# AT32F403Axx register map
Vendor: Keil; Series: AT32F403A; File version: 1.0
CPU: CM4 r0p1, little endian, no MPU, FPU, 4 interrupt priority bits
Registers are 32-bit, read-write, reset 0x0 unless marked. A register's access mark holds for its fields unless they carry their own. Offsets are from the block's base; [hi:lo] are bit positions.

## TMR10 — General purpose timer
Base 0x40015000
Same registers: TMR13 0x40001C00, TMR14 0x40002000, TMR11 0x40015400
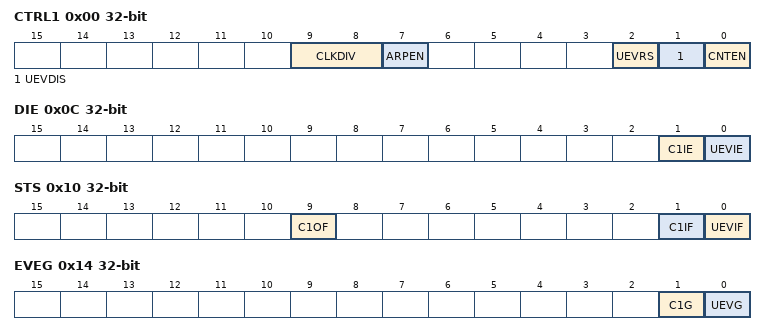
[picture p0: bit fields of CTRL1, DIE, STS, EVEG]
0x00 CTRL1 — control register 1
  [9:8] CLKDIV — Clock division
  [7] ARPEN — Auto-reload preload enable
  [2] UEVRS — Update request source
  [1] UEVDIS — Update disable
  [0] CNTEN — Counter enable
0x0C DIE — DMA/Interrupt enable register
  [1] C1IE — Capture/Compare 1 interrupt enable
  [0] UEVIE — Update interrupt enable
0x10 STS — status register
  [9] C1OF — Capture/Compare 1 overcapture flag
  [1] C1IF — Capture/compare 1 interrupt flag
  [0] UEVIF — Update interrupt flag
0x14 EVEG — event generation register
  [1] C1G — Capture/compare 1 generation
  [0] UEVG — Update generation
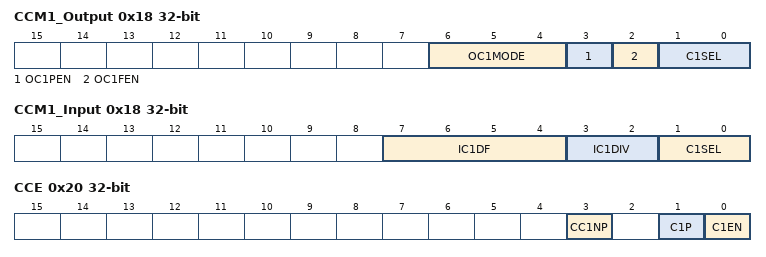
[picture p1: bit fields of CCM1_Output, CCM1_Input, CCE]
0x18 CCM1_Output — capture/compare mode register (output mode)
  [6:4] OC1MODE — Output Compare 1 mode
  [3] OC1PEN — Output Compare 1 preload enable
  [2] OC1FEN — Output Compare 1 fast enable
  [1:0] C1SEL — Capture/Compare 1 selection
0x18 CCM1_Input (alternate view of CCM1_Output) — capture/compare mode register (input mode)
  [7:4] IC1DF — Input capture 1 filter
  [3:2] IC1DIV — Input capture 1 prescaler
  [1:0] C1SEL — Capture/Compare 1 selection
0x20 CCE — capture/compare enable register
  [3] CC1NP — Capture/Compare 1 output Polarity
  [1] C1P — Capture/Compare 1 output Polarity
  [0] C1EN — Capture/Compare 1 output enable
0x24 CNT — counter
  [15:0] CNT — counter value
0x28 DIV — prescaler
  [15:0] DIV — Prescaler value
0x2C AR — auto-reload register
  [15:0] AR — Auto-reload value
0x34 CC1 — capture/compare register 1
  [15:0] CC1 — Capture/Compare 1 value

## ACC — HSI Auto Clock Calibration
Base 0x40015800
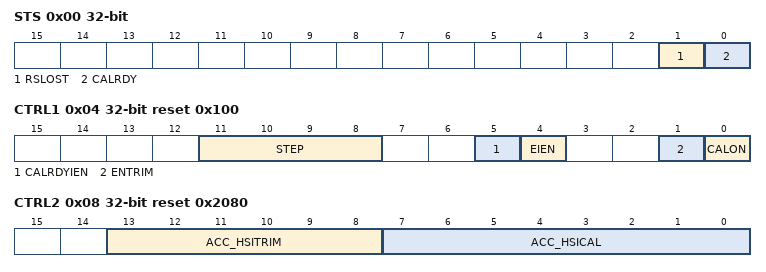
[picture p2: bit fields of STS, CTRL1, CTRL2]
0x00 STS — status register
  [1] RSLOST — Reference Signal Lost
  [0] CALRDY — Internal high-speed clock calibration ready
0x04 CTRL1 reset 0x100 — control register 1
  [11:8] STEP
  [5] CALRDYIEN — CALRDY interrupt enable
  [4] EIEN — RSLOST error interrupt enable
  [1] ENTRIM — Enable trim
  [0] CALON — Calibration on
0x08 CTRL2 reset 0x2080 — control register 2
  [13:8] ACC_HSITRIM ro — Internal high-speed auto clock trimming
  [7:0] ACC_HSICAL ro — Internal high-speed auto clock calibration
0x0C C1 reset 0x1F2C — compare value 1
  [15:0] C1 — Compare 1
0x10 C2 reset 0x1F40 — compare value 2
  [15:0] C2 — Compare 2
0x14 C3 reset 0x1F54 — compare value 3
  [15:0] C3 — Compare 3

## TMR6 — Basic timer
Base 0x40001000
Same registers: TMR7 0x40001400
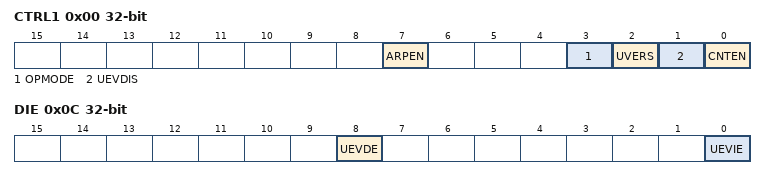
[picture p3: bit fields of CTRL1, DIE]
0x00 CTRL1 — control register 1
  [7] ARPEN — Auto-reload preload enable
  [3] OPMODE — One-pulse mode
  [2] UVERS — Update request source
  [1] UEVDIS — Update disable
  [0] CNTEN — Counter enable
0x04 CTRL2 — control register 2
  [6:4] MMSEL — Master mode selection
0x0C DIE — DMA/Interrupt enable register
  [8] UEVDE — Update DMA request enable
  [0] UEVIE — Update interrupt enable
0x10 STS — status register
  [0] UEVIF — Update interrupt flag
0x14 EVEG — event generation register
  [0] UEVG — Update generation
0x24 CNT — counter
  [15:0] CNT — Low counter value
0x28 DIV — prescaler
  [15:0] DIV — Prescaler value
0x2C AR — auto-reload register
  [15:0] AR — Low Auto-reload value

## I2C1 — Inter integrated circuit
Base 0x40005400
Same registers: I2C2 0x40005800, I2C3 0x40015C00
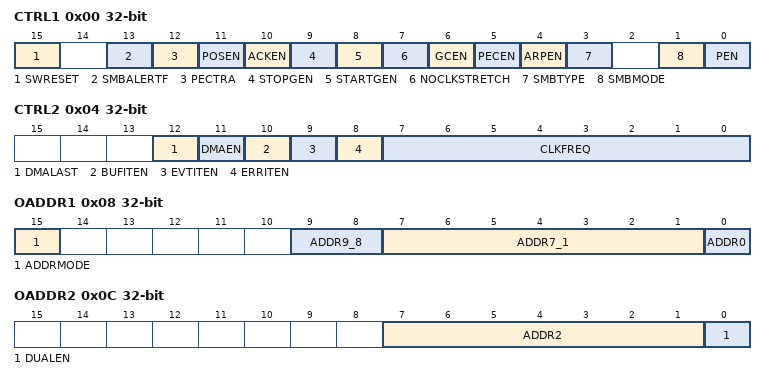
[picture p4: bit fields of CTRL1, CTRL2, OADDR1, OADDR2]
0x00 CTRL1 — Control register 1
  [15] SWRESET — Software reset
  [13] SMBALERTF — SMBus alert
  [12] PECTRA — Packet error checking
  [11] POSEN — Acknowledge/PEC Position (for data reception)
  [10] ACKEN — Acknowledge enable
  [9] STOPGEN — Stop generation
  [8] STARTGEN — Start generation
  [7] NOCLKSTRETCH — Clock stretching disable (Slave mode)
  [6] GCEN — General call enable
  [5] PECEN — PEC enable
  [4] ARPEN — ARP enable
  [3] SMBTYPE — SMBus type
  [1] SMBMODE — SMBus mode
  [0] PEN — Peripheral enable
0x04 CTRL2 — Control register 2
  [12] DMALAST — DMA last transfer
  [11] DMAEN — DMA requests enable
  [10] BUFITEN — Buffer interrupt enable
  [9] EVTITEN — Event interrupt enable
  [8] ERRITEN — Error interrupt enable
  [7:0] CLKFREQ — Peripheral clock frequency
0x08 OADDR1 — Own address register 1
  [15] ADDRMODE — Addressing mode (slave mode)
  [9:8] ADDR9_8 — Interface address bit9 and bit8
  [7:1] ADDR7_1 — Interface address bit7~bit1
  [0] ADDR0 — Interface address bit0
0x0C OADDR2 — Own address register 2
  [7:1] ADDR2 — Interface address
  [0] DUALEN — Dual addressing mode enable
0x10 DT — Data register
  [7:0] DT — 8-bit data register
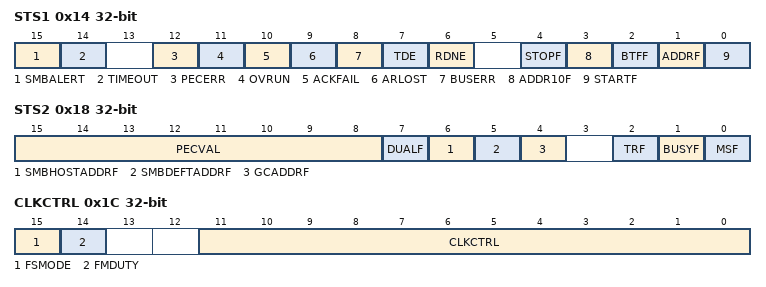
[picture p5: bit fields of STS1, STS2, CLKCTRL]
0x14 STS1 — Status register 1
  [15] SMBALERT — SMBus alert
  [14] TIMEOUT — Timeout or Tlow error
  [12] PECERR — PEC Error in reception
  [11] OVRUN — Overrun/Underrun
  [10] ACKFAIL — Acknowledge failure
  [9] ARLOST — Arbitration lost (master mode)
  [8] BUSERR — Bus error
  [7] TDE ro — Data register empty (transmitters)
  [6] RDNE ro — Data register not empty (receivers)
  [4] STOPF ro — Stop detection (slave mode)
  [3] ADDR10F ro — 10-bit header sent (Master mode)
  [2] BTFF ro — Byte transfer finished
  [1] ADDRF ro — Address sent (master mode)/matched (slave mode)
  [0] STARTF ro — Start bit (Master mode)
0x18 STS2 ro — Status register 2
  [15:8] PECVAL — acket error checking register
  [7] DUALF — Dual flag (Slave mode)
  [6] SMBHOSTADDRF — SMBus host header (Slave mode)
  [5] SMBDEFTADDRF — SMBus device default address (Slave mode)
  [4] GCADDRF — General call address (Slave mode)
  [2] TRF — Transmitter/receiver
  [1] BUSYF — Bus busy
  [0] MSF — Master/slave
0x1C CLKCTRL — Clock control register
  [15] FSMODE — I2C master mode selection
  [14] FMDUTY — Fast mode duty cycle
  [11:0] CLKCTRL — Clock control register in Fast/Standard mode (Master mode)
0x20 TMRISE reset 0x2 — TRISE register
  [5:0] TMRISE — Maximum rise time in Fast/Standard mode (Master mode)
